AUTOSAR XML (schema 00049)
package /RB/PT/PCT_DcmSample_Requester/SwComponentTypes
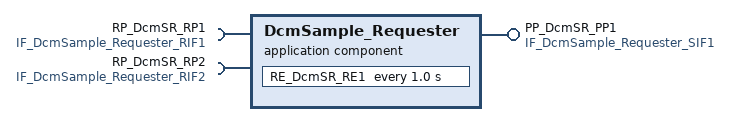
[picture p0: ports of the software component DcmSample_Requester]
  application sw component type DcmSample_Requester
    provide port PP_DcmSR_PP1: provided-interface=IF_DcmSample_Requester_SIF1
    require port RP_DcmSR_RP1: required-interface=IF_DcmSample_Requester_RIF1
    require port RP_DcmSR_RP2: required-interface=IF_DcmSample_Requester_RIF2
    behavior IB_DcmSR_IB1: data-type-mapping=[DTMS_DcmSR_uint8, DTMS_DcmAD_uint8]
      timing event TE_DcmSR_TE1: start-on-event=RE_DcmSR_RE1, period=1.0
      runnable RE_DcmSR_RE1: symbol=DcmSample_Requester_1000ms
        data-receive-point-by-values:
          access DRP_DcmSR_DRP1: accessed-variable=RP_DcmSR_RP1.VDP_DcmSR_RVDP1
        data-send-points:
          access DSP_DcmSR_DSP1: accessed-variable=PP_DcmSR_PP1.VDP_DcmSR_SVDP1
        sync call SSCP_DCMSR_SSCP1: operation=RP_DcmSR_RP2.CSO_DcmSR_CSO1
package /RB/PT/PCT_DcmSample_Requester/PortInterfaces
  sender receiver interface IF_DcmSample_Requester_SIF1
    data VDP_DcmSR_SVDP1: type=ADT_DcmSR_uint8
  sender receiver interface IF_DcmSample_Requester_RIF1
    data VDP_DcmSR_RVDP1: type=ADT_DcmSR_uint8
  client server interface IF_DcmSample_Requester_RIF2
    operation CSO_DcmSR_CSO1: possible-error=[E_NOT_OK, E_OK]
      arg APD_DcmSR_CSO1_APD1: type=ADT_DcmSR_uint8, direction=OUT
    error E_OK: error-code=0
    error E_NOT_OK: error-code=1
package /RB/PT/PCT_DcmSample_Requester/ApplicationDataTypes
  app type ADT_DcmSR_uint8: category=VALUE, sw-calibration-access=READ-ONLY
package /RB/PT/PCT_DcmSample_Requester/ImplementationDataTypes
  impl type IDT_DcmSR_uint8: implementation-data-type=uint8
package /RB/PT/PCT_DcmSample_Requester/DataTypeMappingSets
  data type mapping set DTMS_DcmSR_uint8: data-type-map{application-data-type=ADT_DcmSR_uint8, implementation-data-type=IDT_DcmSR_uint8}
package /RB/PT/PCT_DcmSample_Requester/PortInterfaceMappingSets
  port interface mapping set PIMSet_IF_DcmSample_Requester_RIF2_IF_DcmSample_Adapter_SIF1
    port-interface-mappings:
      client server interface mapping PIM_CSO_DcmSR_CSO1_CSO_DcmAD_CSO1: client-server-operation-mapping{data-prototype-mapping{first-data-prototype=APD_DcmSR_CSO1_APD1, second-data-prototype=APD_DcmAD_CSO1_APD1}, first-operation=CSO_DcmSR_CSO1, second-operation=CSO_DcmAD_CSO1}
  port interface mapping set PIMSet_IF_DcmSample_Requester_RIF1_IF_DcmSample_Provider_SIF1
    port-interface-mappings:
      variable and parameter interface mapping PIM_VDP_DcmSR_RVDP1_VDP_DcmSP_SVDP1: data-prototype-mapping{first-data-prototype=VDP_DcmSR_RVDP1, second-data-prototype=VDP_DcmSP_SVDP1}
